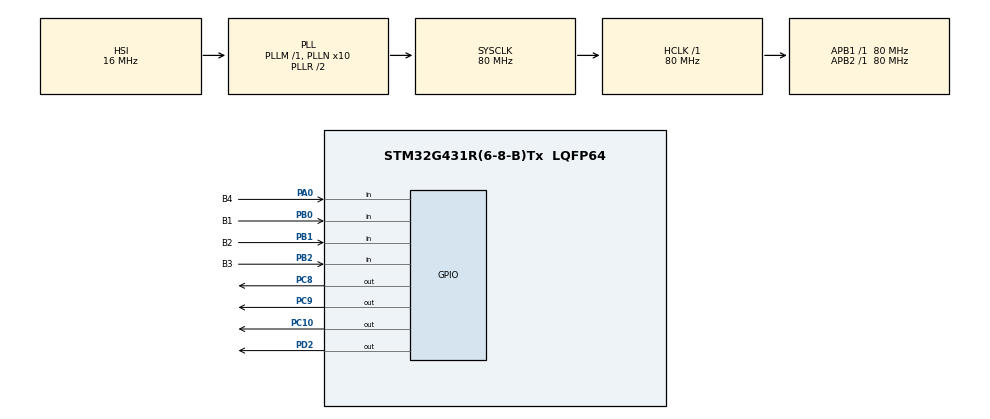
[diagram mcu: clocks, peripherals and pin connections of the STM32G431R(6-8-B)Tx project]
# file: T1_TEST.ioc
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Mcu.Family=STM32G4
Mcu.Name=STM32G431R(6-8-B)Tx
Mcu.Package=LQFP64
NVIC.PriorityGroup=NVIC_PRIORITYGROUP_4
PA0.GPIO_Label=B4
PA0.GPIO_PuPd=GPIO_PULLUP
PA0.Signal=GPIO_Input
PA13.Mode=Serial_Wire
PA13.Signal=SYS_JTMS-SWDIO
PA14.Mode=Serial_Wire
PA14.Signal=SYS_JTCK-SWCLK
PB0.GPIO_Label=B1
PB0.GPIO_PuPd=GPIO_PULLUP
PB0.Signal=GPIO_Input
PB1.GPIO_Label=B2
PB1.GPIO_PuPd=GPIO_PULLUP
PB1.Signal=GPIO_Input
PB2.GPIO_Label=B3
PB2.GPIO_PuPd=GPIO_PULLUP
PB2.Signal=GPIO_Input
PC10.PinState=GPIO_PIN_SET
PC10.Signal=GPIO_Output
PC8.PinState=GPIO_PIN_SET
PC8.Signal=GPIO_Output
PC9.PinState=GPIO_PIN_SET
PC9.Signal=GPIO_Output
PD2.PinState=GPIO_PIN_SET
PD2.Signal=GPIO_Output
PF0-OSC_IN.Mode=HSE-External-Oscillator
PF0-OSC_IN.Signal=RCC_OSC_IN
PF1-OSC_OUT.Mode=HSE-External-Oscillator
PF1-OSC_OUT.Signal=RCC_OSC_OUT
ProjectManager.HeapSize=0x200
ProjectManager.StackSize=0x400
ProjectManager.TargetToolchain=MDK-ARM V5.32
RCC.ADC12Freq_Value=80000000
RCC.AHBFreq_Value=80000000
RCC.APB1Freq_Value=80000000
RCC.APB1TimFreq_Value=80000000
RCC.APB2Freq_Value=80000000
RCC.APB2TimFreq_Value=80000000
RCC.CortexFreq_Value=80000000
RCC.EXTERNAL_CLOCK_VALUE=12288000
RCC.HCLKFreq_Value=80000000
RCC.HSE_VALUE=8000000
RCC.HSI48_VALUE=48000000
RCC.HSI_VALUE=16000000
RCC.LSE_VALUE=32768
RCC.PLLN=10
RCC.SYSCLKFreq_VALUE=80000000
RCC.SYSCLKSource=RCC_SYSCLKSOURCE_PLLCLK
RCC.USBFreq_Value=80000000
RCC.VCOOutputFreq_Value=160000000
VP_SYS_VS_DBSignals.Mode=DisableDeadBatterySignals
board=custom

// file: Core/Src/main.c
/* USER CODE BEGIN Header */
/**
  ******************************************************************************
  * @file           : main.c
  * @brief          : Main program body
  ******************************************************************************
  * @attention
  *
  * Copyright (c) 2024 STMicroelectronics.
  * All rights reserved.
  *
  * This software is licensed under terms that can be found in the LICENSE file
  * in the root directory of this software component.
  * If no LICENSE file comes with this software, it is provided AS-IS.
  *
  ******************************************************************************
  */
/* USER CODE END Header */
#include "main.h"

void SystemClock_Config(void);
static void MX_GPIO_Init(void);

int main(void)
{

  /* MCU Configuration--------------------------------------------------------*/

  /* Reset of all peripherals, Initializes the Flash interface and the Systick. */
  HAL_Init();

  /* Configure the system clock */
  SystemClock_Config();

  /* Initialize all configured peripherals */
  MX_GPIO_Init();

  /* Infinite loop */
  /* USER CODE BEGIN WHILE */
  while (1)
  {
	  key_scan();
    /* USER CODE END WHILE */

  }
}

void SystemClock_Config(void)
{
  RCC_OscInitTypeDef RCC_OscInitStruct = {0};
  RCC_ClkInitTypeDef RCC_ClkInitStruct = {0};

  /** Configure the main internal regulator output voltage
  */
  HAL_PWREx_ControlVoltageScaling(PWR_REGULATOR_VOLTAGE_SCALE1);

  /** Initializes the RCC Oscillators according to the specified parameters
  * in the RCC_OscInitTypeDef structure.
  */
  RCC_OscInitStruct.OscillatorType = RCC_OSCILLATORTYPE_HSI;
  RCC_OscInitStruct.HSIState = RCC_HSI_ON;
  RCC_OscInitStruct.HSICalibrationValue = RCC_HSICALIBRATION_DEFAULT;
  RCC_OscInitStruct.PLL.PLLState = RCC_PLL_ON;
  RCC_OscInitStruct.PLL.PLLSource = RCC_PLLSOURCE_HSI;
  RCC_OscInitStruct.PLL.PLLM = RCC_PLLM_DIV1;
  RCC_OscInitStruct.PLL.PLLN = 10;
  RCC_OscInitStruct.PLL.PLLP = RCC_PLLP_DIV2;
  RCC_OscInitStruct.PLL.PLLQ = RCC_PLLQ_DIV2;
  RCC_OscInitStruct.PLL.PLLR = RCC_PLLR_DIV2;
  if (HAL_RCC_OscConfig(&RCC_OscInitStruct) != HAL_OK)
  {
    Error_Handler();
  }

  /** Initializes the CPU, AHB and APB buses clocks
  */
  RCC_ClkInitStruct.ClockType = RCC_CLOCKTYPE_HCLK|RCC_CLOCKTYPE_SYSCLK
                              |RCC_CLOCKTYPE_PCLK1|RCC_CLOCKTYPE_PCLK2;
  RCC_ClkInitStruct.SYSCLKSource = RCC_SYSCLKSOURCE_PLLCLK;
  RCC_ClkInitStruct.AHBCLKDivider = RCC_SYSCLK_DIV1;
  RCC_ClkInitStruct.APB1CLKDivider = RCC_HCLK_DIV1;
  RCC_ClkInitStruct.APB2CLKDivider = RCC_HCLK_DIV1;

  if (HAL_RCC_ClockConfig(&RCC_ClkInitStruct, FLASH_LATENCY_2) != HAL_OK)
  {
    Error_Handler();
  }
}

static void MX_GPIO_Init(void)
{
  GPIO_InitTypeDef GPIO_InitStruct = {0};

  /* GPIO Ports Clock Enable */
  __HAL_RCC_GPIOF_CLK_ENABLE();
  __HAL_RCC_GPIOA_CLK_ENABLE();
  __HAL_RCC_GPIOB_CLK_ENABLE();
  __HAL_RCC_GPIOC_CLK_ENABLE();
  __HAL_RCC_GPIOD_CLK_ENABLE();

  /*Configure GPIO pin Output Level */
  HAL_GPIO_WritePin(GPIOC, GPIO_PIN_8|GPIO_PIN_9|GPIO_PIN_10, GPIO_PIN_SET);

  /*Configure GPIO pin Output Level */
  HAL_GPIO_WritePin(GPIOD, GPIO_PIN_2, GPIO_PIN_SET);

  /*Configure GPIO pin : B4_Pin */
  GPIO_InitStruct.Pin = B4_Pin;
  GPIO_InitStruct.Mode = GPIO_MODE_INPUT;
  GPIO_InitStruct.Pull = GPIO_PULLUP;
  HAL_GPIO_Init(B4_GPIO_Port, &GPIO_InitStruct);

  /*Configure GPIO pins : B1_Pin B2_Pin B3_Pin */
  GPIO_InitStruct.Pin = B1_Pin|B2_Pin|B3_Pin;
  GPIO_InitStruct.Mode = GPIO_MODE_INPUT;
  GPIO_InitStruct.Pull = GPIO_PULLUP;
  HAL_GPIO_Init(GPIOB, &GPIO_InitStruct);

  /*Configure GPIO pins : PC8 PC9 PC10 */
  GPIO_InitStruct.Pin = GPIO_PIN_8|GPIO_PIN_9|GPIO_PIN_10;
  GPIO_InitStruct.Mode = GPIO_MODE_OUTPUT_PP;
  GPIO_InitStruct.Pull = GPIO_NOPULL;
  GPIO_InitStruct.Speed = GPIO_SPEED_FREQ_LOW;
  HAL_GPIO_Init(GPIOC, &GPIO_InitStruct);

  /*Configure GPIO pin : PD2 */
  GPIO_InitStruct.Pin = GPIO_PIN_2;
  GPIO_InitStruct.Mode = GPIO_MODE_OUTPUT_PP;
  GPIO_InitStruct.Pull = GPIO_NOPULL;
  GPIO_InitStruct.Speed = GPIO_SPEED_FREQ_LOW;
  HAL_GPIO_Init(GPIOD, &GPIO_InitStruct);

}

void Error_Handler(void)
{
  __disable_irq();
  while (1)
  {
  }
}
